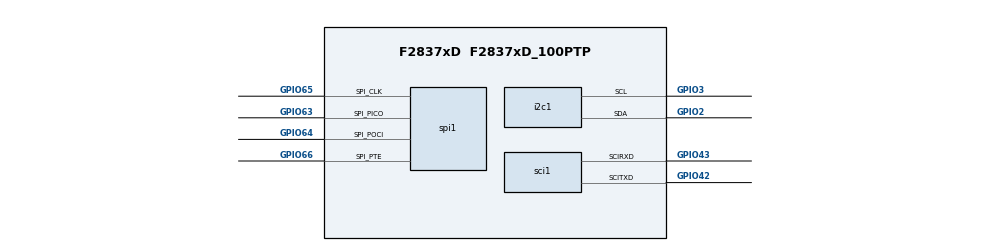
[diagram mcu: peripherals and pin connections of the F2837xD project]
/**
 * @cliArgs --device "F2837xD" --part "F2837xD_100PTP" --package "F2837xD_100PTP" --context "CPU1" --product "C2000WARE@6.00.01.00"
 * @versions {"tool":"1.26.0+4407"}
 */

/**
 * Import the modules used in this configuration.
 */
const adc  = scripting.addModule("/driverlib/adc.js", {}, false);
const adc1 = adc.addInstance();
const adc2 = adc.addInstance();
const i2c  = scripting.addModule("/driverlib/i2c.js", {}, false);
const i2c1 = i2c.addInstance();
const sci  = scripting.addModule("/driverlib/sci.js", {}, false);
const sci1 = sci.addInstance();
const spi  = scripting.addModule("/driverlib/spi.js", {}, false);
const spi1 = spi.addInstance();

/**
 * Write custom configuration values to the imported modules.
 */
adc1.adcClockPrescaler       = "ADC_CLK_DIV_4_0";
adc1.soc0Name                = "J3P30";
adc1.soc0SampleWindow        = 50;
adc1.$name                   = "myADCA";
adc1.soc2SampleWindow        = 50;
adc1.soc3Name                = "J3P26";
adc1.soc3Channel             = "ADC_CH_ADCIN3";
adc1.soc3SampleWindow        = 50;
adc1.enabledInts             = ["ADC_INT_NUMBER1"];
adc1.interruptPulseMode      = "ADC_PULSE_END_OF_CONV";
adc1.enableInterrupt1        = true;
adc1.enabledSOCs             = ["ADC_SOC_NUMBER0","ADC_SOC_NUMBER1","ADC_SOC_NUMBER2"];
adc1.soc1Name                = "J3P29";
adc1.soc1Channel             = "ADC_CH_ADCIN2";
adc1.soc1SampleWindow        = 50;
adc1.soc2Name                = "J3P26";
adc1.soc2Channel             = "ADC_CH_ADCIN3";
adc1.interrupt1SOCSource     = "ADC_SOC_NUMBER2";
adc1.soc0IndependentNameMode = true;
adc1.soc1IndependentNameMode = true;
adc1.soc2IndependentNameMode = true;

adc2.adcBase                 = "ADCB_BASE";
adc2.$name                   = "myADCB";
adc2.adcClockPrescaler       = "ADC_CLK_DIV_4_0";
adc2.enabledSOCs             = ["ADC_SOC_NUMBER0","ADC_SOC_NUMBER1"];
adc2.soc0Name                = "J3P28";
adc2.soc0Channel             = "ADC_CH_ADCIN2";
adc2.soc0SampleWindow        = 50;
adc2.soc1Name                = "J3P25";
adc2.soc1Channel             = "ADC_CH_ADCIN3";
adc2.soc1SampleWindow        = 50;
adc2.interruptPulseMode      = "ADC_PULSE_END_OF_CONV";
adc2.enabledInts             = ["ADC_INT_NUMBER1"];
adc2.interrupt1SOCSource     = "ADC_SOC_NUMBER1";
adc2.enableInterrupt1        = true;
adc2.soc0IndependentNameMode = true;
adc2.soc1IndependentNameMode = true;

i2c1.$name              = "myI2C0";
i2c1.bitCount           = "I2C_BITCOUNT_8";
i2c1.targetAddress      = 0x76;
i2c1.emulationMode      = "I2C_EMULATION_FREE_RUN";
i2c1.useFifo            = false;
i2c1.i2c.$assign        = "I2CB";
i2c1.i2c.sdaPin.$assign = "GPIO2";
i2c1.i2c.sclPin.$assign = "GPIO3";
i2c1.sdaQual.padConfig  = "OD_PULLUP";
i2c1.sclQual.padConfig  = "OD_PULLUP";

sci1.$name                 = "mySCI0";
sci1.baudRates             = 9600;
sci1.sci.$assign           = "SCIA";
sci1.sci.scirxdPin.$assign = "GPIO43";
sci1.sci.scitxdPin.$assign = "GPIO42";
sci1.rxQual.$name          = "myGPIOQUAL0";
sci1.txQual.$name          = "myGPIOQUAL1";

spi1.$name                   = "mySPI0";
spi1.mode                    = "SPI_MODE_CONTROLLER";
spi1.useInterrupts           = false;
spi1.spi.spi_picoPin.$assign = "GPIO63";
spi1.spi.spi_pociPin.$assign = "GPIO64";
spi1.spi.spi_clkPin.$assign  = "GPIO65";
spi1.spi.spi_ptePin.$assign  = "GPIO66";
spi1.picoQual.$name          = "myGPIOQUAL2";
spi1.pociQual.$name          = "myGPIOQUAL3";
spi1.clkQual.$name           = "myGPIOQUAL4";
spi1.pteQual.$name           = "myGPIOQUAL5";

/**
 * Pinmux solution for unlocked pins/peripherals. This ensures that minor changes to the automatic solver in a future
 * version of the tool will not impact the pinmux you originally saw.  These lines can be completely deleted in order to
 * re-solve from scratch.
 */
spi1.spi.$suggestSolution = "SPIB";
